VERSION "10.8"

NS_ :

BS_:

BU_: SCC ESR
VAL_TABLE_ Value_Table_Track_Status 7 "New Coasting Target" 6 "Invalid Coasting Target" 5 "Merged Target" 4 "Coasting Target" 3 "Updated Target" 2 "New Updated Target" 1 "New Target" 0 "No Target" ;

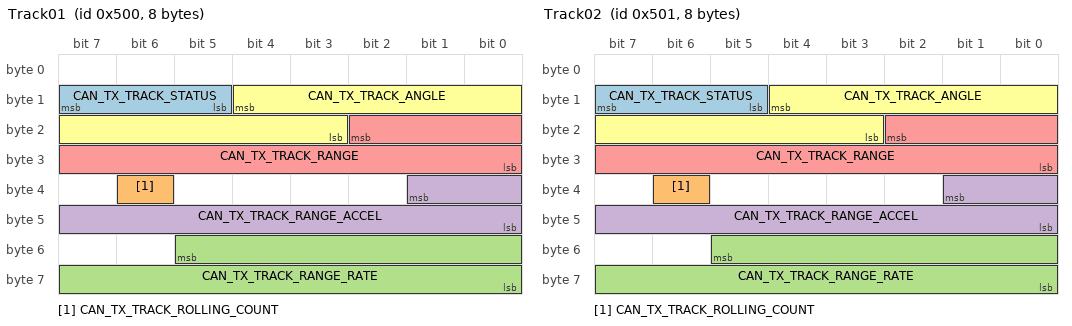
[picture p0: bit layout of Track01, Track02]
BO_ 1280 Track01: 8 ESR
 SG_ CAN_TX_TRACK_STATUS : 15|3@0+ (1,0) [0|7] "" Vector__XXX
 SG_ CAN_TX_TRACK_ROLLING_COUNT : 38|1@0+ (1,0) [0|1] "" Vector__XXX
 SG_ CAN_TX_TRACK_RANGE_RATE : 53|14@0- (0.01,0) [-81.92|81.91] "m/s" Vector__XXX
 SG_ CAN_TX_TRACK_RANGE_ACCEL : 33|10@0- (0.05,0) [-25.6|25.55] "m/s/s" Vector__XXX
 SG_ CAN_TX_TRACK_RANGE : 18|11@0+ (0.1,0) [0|204.7] "m" Vector__XXX
 SG_ CAN_TX_TRACK_ANGLE : 12|10@0- (0.1,0) [-51.2|51.1] "deg" Vector__XXX

BO_ 1281 Track02: 8 ESR
 SG_ CAN_TX_TRACK_STATUS : 15|3@0+ (1,0) [0|7] "" Vector__XXX
 SG_ CAN_TX_TRACK_ROLLING_COUNT : 38|1@0+ (1,0) [0|1] "" Vector__XXX
 SG_ CAN_TX_TRACK_RANGE_RATE : 53|14@0- (0.01,0) [-81.92|81.91] "m/s" Vector__XXX
 SG_ CAN_TX_TRACK_RANGE_ACCEL : 33|10@0- (0.05,0) [-25.6|25.55] "m/s/s" Vector__XXX
 SG_ CAN_TX_TRACK_RANGE : 18|11@0+ (0.1,0) [0|204.7] "m" Vector__XXX
 SG_ CAN_TX_TRACK_ANGLE : 12|10@0- (0.1,0) [-51.2|51.1] "deg" Vector__XXX

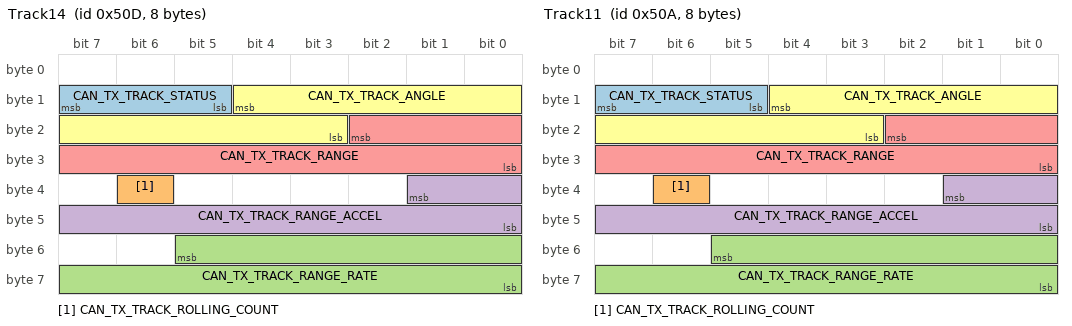
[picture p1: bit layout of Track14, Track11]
BO_ 1293 Track14: 8 ESR
 SG_ CAN_TX_TRACK_STATUS : 15|3@0+ (1,0) [0|7] "" Vector__XXX
 SG_ CAN_TX_TRACK_ROLLING_COUNT : 38|1@0+ (1,0) [0|1] "" Vector__XXX
 SG_ CAN_TX_TRACK_RANGE_RATE : 53|14@0- (0.01,0) [-81.92|81.91] "m/s" Vector__XXX
 SG_ CAN_TX_TRACK_RANGE_ACCEL : 33|10@0- (0.05,0) [-25.6|25.55] "m/s/s" Vector__XXX
 SG_ CAN_TX_TRACK_RANGE : 18|11@0+ (0.1,0) [0|204.7] "m" Vector__XXX
 SG_ CAN_TX_TRACK_ANGLE : 12|10@0- (0.1,0) [-51.2|51.1] "deg" Vector__XXX

BO_ 1290 Track11: 8 ESR
 SG_ CAN_TX_TRACK_STATUS : 15|3@0+ (1,0) [0|7] "" Vector__XXX
 SG_ CAN_TX_TRACK_ROLLING_COUNT : 38|1@0+ (1,0) [0|1] "" Vector__XXX
 SG_ CAN_TX_TRACK_RANGE_RATE : 53|14@0- (0.01,0) [-81.92|81.91] "m/s" Vector__XXX
 SG_ CAN_TX_TRACK_RANGE_ACCEL : 33|10@0- (0.05,0) [-25.6|25.55] "m/s/s" Vector__XXX
 SG_ CAN_TX_TRACK_RANGE : 18|11@0+ (0.1,0) [0|204.7] "m" Vector__XXX
 SG_ CAN_TX_TRACK_ANGLE : 12|10@0- (0.1,0) [-51.2|51.1] "deg" Vector__XXX

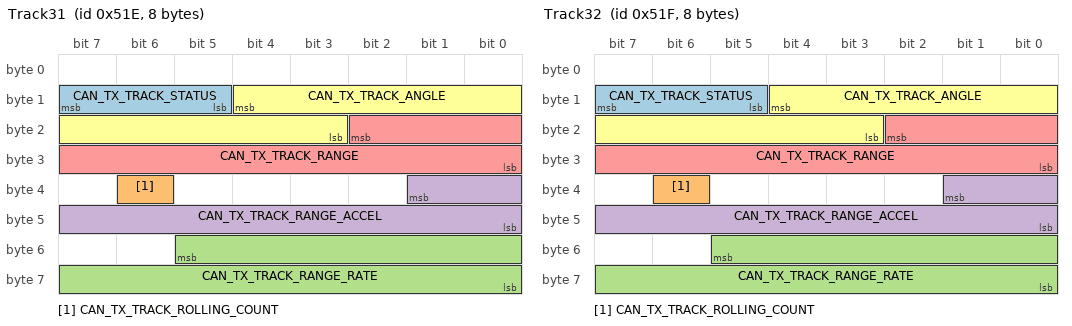
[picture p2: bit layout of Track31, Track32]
BO_ 1310 Track31: 8 ESR
 SG_ CAN_TX_TRACK_STATUS : 15|3@0+ (1,0) [0|7] "" Vector__XXX
 SG_ CAN_TX_TRACK_ROLLING_COUNT : 38|1@0+ (1,0) [0|1] "" Vector__XXX
 SG_ CAN_TX_TRACK_RANGE_RATE : 53|14@0- (0.01,0) [-81.92|81.91] "m/s" Vector__XXX
 SG_ CAN_TX_TRACK_RANGE_ACCEL : 33|10@0- (0.05,0) [-25.6|25.55] "m/s/s" Vector__XXX
 SG_ CAN_TX_TRACK_RANGE : 18|11@0+ (0.1,0) [0|204.7] "m" Vector__XXX
 SG_ CAN_TX_TRACK_ANGLE : 12|10@0- (0.1,0) [-51.2|51.1] "deg" Vector__XXX

BO_ 1311 Track32: 8 ESR
 SG_ CAN_TX_TRACK_STATUS : 15|3@0+ (1,0) [0|7] "" Vector__XXX
 SG_ CAN_TX_TRACK_ROLLING_COUNT : 38|1@0+ (1,0) [0|1] "" Vector__XXX
 SG_ CAN_TX_TRACK_RANGE_RATE : 53|14@0- (0.01,0) [-81.92|81.91] "m/s" Vector__XXX
 SG_ CAN_TX_TRACK_RANGE_ACCEL : 33|10@0- (0.05,0) [-25.6|25.55] "m/s/s" Vector__XXX
 SG_ CAN_TX_TRACK_RANGE : 18|11@0+ (0.1,0) [0|204.7] "m" Vector__XXX
 SG_ CAN_TX_TRACK_ANGLE : 12|10@0- (0.1,0) [-51.2|51.1] "deg" Vector__XXX

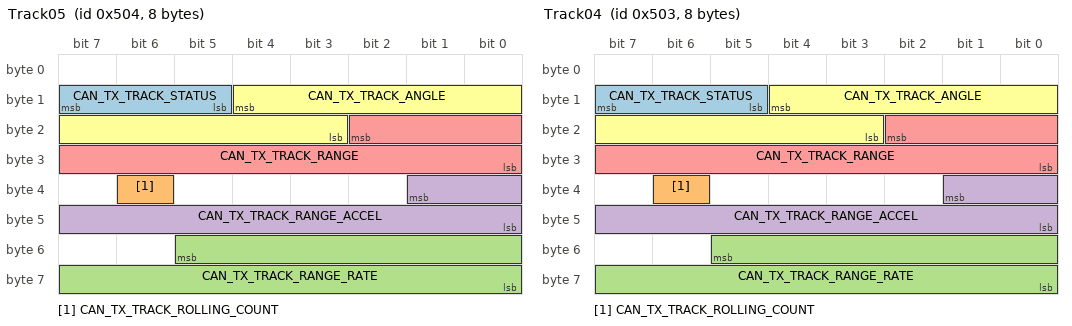
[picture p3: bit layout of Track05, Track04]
BO_ 1284 Track05: 8 ESR
 SG_ CAN_TX_TRACK_STATUS : 15|3@0+ (1,0) [0|7] "" Vector__XXX
 SG_ CAN_TX_TRACK_ROLLING_COUNT : 38|1@0+ (1,0) [0|1] "" Vector__XXX
 SG_ CAN_TX_TRACK_RANGE_RATE : 53|14@0- (0.01,0) [-81.92|81.91] "m/s" Vector__XXX
 SG_ CAN_TX_TRACK_RANGE_ACCEL : 33|10@0- (0.05,0) [-25.6|25.55] "m/s/s" Vector__XXX
 SG_ CAN_TX_TRACK_RANGE : 18|11@0+ (0.1,0) [0|204.7] "m" Vector__XXX
 SG_ CAN_TX_TRACK_ANGLE : 12|10@0- (0.1,0) [-51.2|51.1] "deg" Vector__XXX

BO_ 1283 Track04: 8 ESR
 SG_ CAN_TX_TRACK_STATUS : 15|3@0+ (1,0) [0|7] "" Vector__XXX
 SG_ CAN_TX_TRACK_ROLLING_COUNT : 38|1@0+ (1,0) [0|1] "" Vector__XXX
 SG_ CAN_TX_TRACK_RANGE_RATE : 53|14@0- (0.01,0) [-81.92|81.91] "m/s" Vector__XXX
 SG_ CAN_TX_TRACK_RANGE_ACCEL : 33|10@0- (0.05,0) [-25.6|25.55] "m/s/s" Vector__XXX
 SG_ CAN_TX_TRACK_RANGE : 18|11@0+ (0.1,0) [0|204.7] "m" Vector__XXX
 SG_ CAN_TX_TRACK_ANGLE : 12|10@0- (0.1,0) [-51.2|51.1] "deg" Vector__XXX

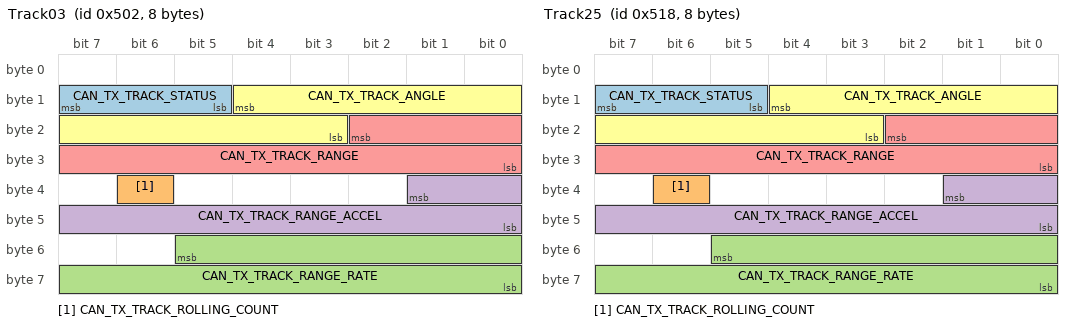
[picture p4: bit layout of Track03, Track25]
BO_ 1282 Track03: 8 ESR
 SG_ CAN_TX_TRACK_STATUS : 15|3@0+ (1,0) [0|7] "" Vector__XXX
 SG_ CAN_TX_TRACK_ROLLING_COUNT : 38|1@0+ (1,0) [0|1] "" Vector__XXX
 SG_ CAN_TX_TRACK_RANGE_RATE : 53|14@0- (0.01,0) [-81.92|81.91] "m/s" Vector__XXX
 SG_ CAN_TX_TRACK_RANGE_ACCEL : 33|10@0- (0.05,0) [-25.6|25.55] "m/s/s" Vector__XXX
 SG_ CAN_TX_TRACK_RANGE : 18|11@0+ (0.1,0) [0|204.7] "m" Vector__XXX
 SG_ CAN_TX_TRACK_ANGLE : 12|10@0- (0.1,0) [-51.2|51.1] "deg" Vector__XXX

BO_ 1304 Track25: 8 ESR
 SG_ CAN_TX_TRACK_STATUS : 15|3@0+ (1,0) [0|7] "" Vector__XXX
 SG_ CAN_TX_TRACK_ROLLING_COUNT : 38|1@0+ (1,0) [0|1] "" Vector__XXX
 SG_ CAN_TX_TRACK_RANGE_RATE : 53|14@0- (0.01,0) [-81.92|81.91] "m/s" Vector__XXX
 SG_ CAN_TX_TRACK_RANGE_ACCEL : 33|10@0- (0.05,0) [-25.6|25.55] "m/s/s" Vector__XXX
 SG_ CAN_TX_TRACK_RANGE : 18|11@0+ (0.1,0) [0|204.7] "m" Vector__XXX
 SG_ CAN_TX_TRACK_ANGLE : 12|10@0- (0.1,0) [-51.2|51.1] "deg" Vector__XXX

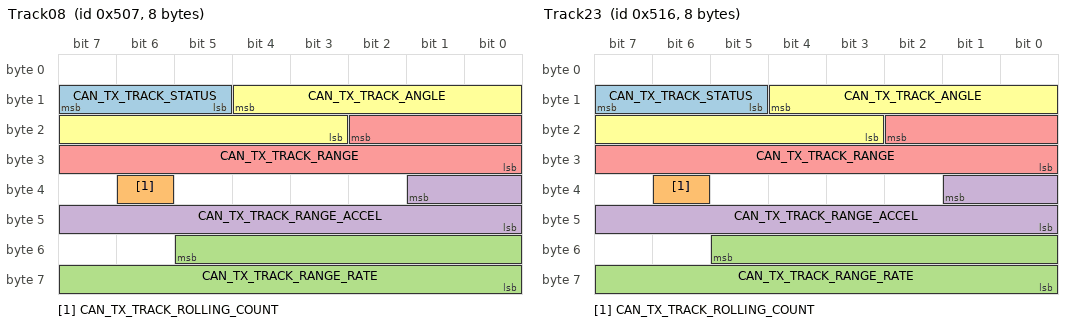
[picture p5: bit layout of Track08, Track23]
BO_ 1287 Track08: 8 ESR
 SG_ CAN_TX_TRACK_STATUS : 15|3@0+ (1,0) [0|7] "" Vector__XXX
 SG_ CAN_TX_TRACK_ROLLING_COUNT : 38|1@0+ (1,0) [0|1] "" Vector__XXX
 SG_ CAN_TX_TRACK_RANGE_RATE : 53|14@0- (0.01,0) [-81.92|81.91] "m/s" Vector__XXX
 SG_ CAN_TX_TRACK_RANGE_ACCEL : 33|10@0- (0.05,0) [-25.6|25.55] "m/s/s" Vector__XXX
 SG_ CAN_TX_TRACK_RANGE : 18|11@0+ (0.1,0) [0|204.7] "m" Vector__XXX
 SG_ CAN_TX_TRACK_ANGLE : 12|10@0- (0.1,0) [-51.2|51.1] "deg" Vector__XXX

BO_ 1302 Track23: 8 ESR
 SG_ CAN_TX_TRACK_STATUS : 15|3@0+ (1,0) [0|7] "" Vector__XXX
 SG_ CAN_TX_TRACK_ROLLING_COUNT : 38|1@0+ (1,0) [0|1] "" Vector__XXX
 SG_ CAN_TX_TRACK_RANGE_RATE : 53|14@0- (0.01,0) [-81.92|81.91] "m/s" Vector__XXX
 SG_ CAN_TX_TRACK_RANGE_ACCEL : 33|10@0- (0.05,0) [-25.6|25.55] "m/s/s" Vector__XXX
 SG_ CAN_TX_TRACK_RANGE : 18|11@0+ (0.1,0) [0|204.7] "m" Vector__XXX
 SG_ CAN_TX_TRACK_ANGLE : 12|10@0- (0.1,0) [-51.2|51.1] "deg" Vector__XXX

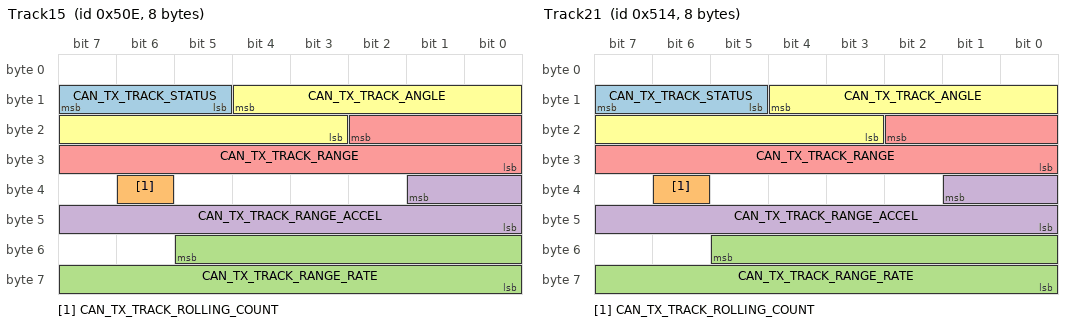
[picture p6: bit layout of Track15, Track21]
BO_ 1294 Track15: 8 ESR
 SG_ CAN_TX_TRACK_STATUS : 15|3@0+ (1,0) [0|7] "" Vector__XXX
 SG_ CAN_TX_TRACK_ROLLING_COUNT : 38|1@0+ (1,0) [0|1] "" Vector__XXX
 SG_ CAN_TX_TRACK_RANGE_RATE : 53|14@0- (0.01,0) [-81.92|81.91] "m/s" Vector__XXX
 SG_ CAN_TX_TRACK_RANGE_ACCEL : 33|10@0- (0.05,0) [-25.6|25.55] "m/s/s" Vector__XXX
 SG_ CAN_TX_TRACK_RANGE : 18|11@0+ (0.1,0) [0|204.7] "m" Vector__XXX
 SG_ CAN_TX_TRACK_ANGLE : 12|10@0- (0.1,0) [-51.2|51.1] "deg" Vector__XXX

BO_ 1300 Track21: 8 ESR
 SG_ CAN_TX_TRACK_STATUS : 15|3@0+ (1,0) [0|7] "" Vector__XXX
 SG_ CAN_TX_TRACK_ROLLING_COUNT : 38|1@0+ (1,0) [0|1] "" Vector__XXX
 SG_ CAN_TX_TRACK_RANGE_RATE : 53|14@0- (0.01,0) [-81.92|81.91] "m/s" Vector__XXX
 SG_ CAN_TX_TRACK_RANGE_ACCEL : 33|10@0- (0.05,0) [-25.6|25.55] "m/s/s" Vector__XXX
 SG_ CAN_TX_TRACK_RANGE : 18|11@0+ (0.1,0) [0|204.7] "m" Vector__XXX
 SG_ CAN_TX_TRACK_ANGLE : 12|10@0- (0.1,0) [-51.2|51.1] "deg" Vector__XXX

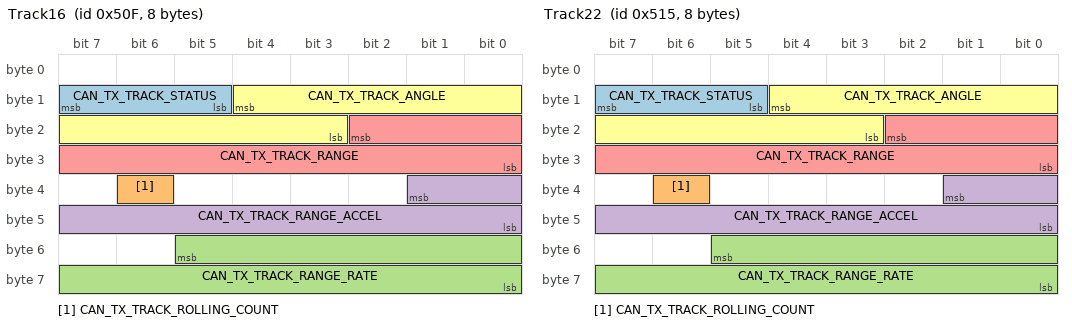
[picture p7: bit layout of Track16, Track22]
BO_ 1295 Track16: 8 ESR
 SG_ CAN_TX_TRACK_STATUS : 15|3@0+ (1,0) [0|7] "" Vector__XXX
 SG_ CAN_TX_TRACK_ROLLING_COUNT : 38|1@0+ (1,0) [0|1] "" Vector__XXX
 SG_ CAN_TX_TRACK_RANGE_RATE : 53|14@0- (0.01,0) [-81.92|81.91] "m/s" Vector__XXX
 SG_ CAN_TX_TRACK_RANGE_ACCEL : 33|10@0- (0.05,0) [-25.6|25.55] "m/s/s" Vector__XXX
 SG_ CAN_TX_TRACK_RANGE : 18|11@0+ (0.1,0) [0|204.7] "m" Vector__XXX
 SG_ CAN_TX_TRACK_ANGLE : 12|10@0- (0.1,0) [-51.2|51.1] "deg" Vector__XXX

BO_ 1301 Track22: 8 ESR
 SG_ CAN_TX_TRACK_STATUS : 15|3@0+ (1,0) [0|7] "" Vector__XXX
 SG_ CAN_TX_TRACK_ROLLING_COUNT : 38|1@0+ (1,0) [0|1] "" Vector__XXX
 SG_ CAN_TX_TRACK_RANGE_RATE : 53|14@0- (0.01,0) [-81.92|81.91] "m/s" Vector__XXX
 SG_ CAN_TX_TRACK_RANGE_ACCEL : 33|10@0- (0.05,0) [-25.6|25.55] "m/s/s" Vector__XXX
 SG_ CAN_TX_TRACK_RANGE : 18|11@0+ (0.1,0) [0|204.7] "m" Vector__XXX
 SG_ CAN_TX_TRACK_ANGLE : 12|10@0- (0.1,0) [-51.2|51.1] "deg" Vector__XXX

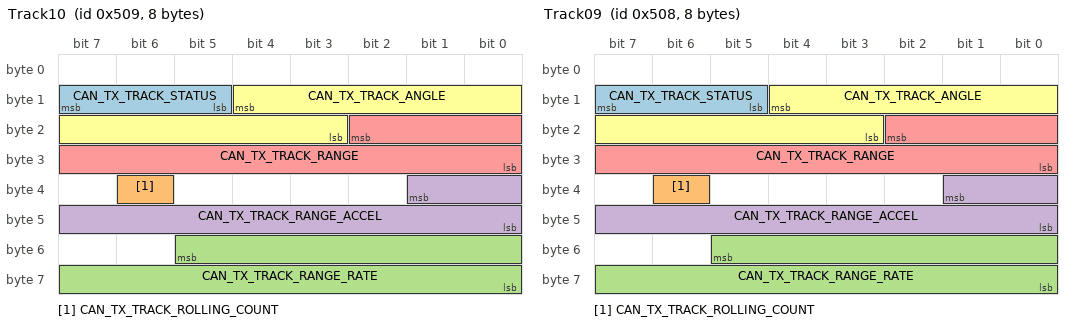
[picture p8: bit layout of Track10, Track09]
BO_ 1289 Track10: 8 ESR
 SG_ CAN_TX_TRACK_STATUS : 15|3@0+ (1,0) [0|7] "" Vector__XXX
 SG_ CAN_TX_TRACK_ROLLING_COUNT : 38|1@0+ (1,0) [0|1] "" Vector__XXX
 SG_ CAN_TX_TRACK_RANGE_RATE : 53|14@0- (0.01,0) [-81.92|81.91] "m/s" Vector__XXX
 SG_ CAN_TX_TRACK_RANGE_ACCEL : 33|10@0- (0.05,0) [-25.6|25.55] "m/s/s" Vector__XXX
 SG_ CAN_TX_TRACK_RANGE : 18|11@0+ (0.1,0) [0|204.7] "m" Vector__XXX
 SG_ CAN_TX_TRACK_ANGLE : 12|10@0- (0.1,0) [-51.2|51.1] "deg" Vector__XXX

BO_ 1288 Track09: 8 ESR
 SG_ CAN_TX_TRACK_STATUS : 15|3@0+ (1,0) [0|7] "" Vector__XXX
 SG_ CAN_TX_TRACK_ROLLING_COUNT : 38|1@0+ (1,0) [0|1] "" Vector__XXX
 SG_ CAN_TX_TRACK_RANGE_RATE : 53|14@0- (0.01,0) [-81.92|81.91] "m/s" Vector__XXX
 SG_ CAN_TX_TRACK_RANGE_ACCEL : 33|10@0- (0.05,0) [-25.6|25.55] "m/s/s" Vector__XXX
 SG_ CAN_TX_TRACK_RANGE : 18|11@0+ (0.1,0) [0|204.7] "m" Vector__XXX
 SG_ CAN_TX_TRACK_ANGLE : 12|10@0- (0.1,0) [-51.2|51.1] "deg" Vector__XXX

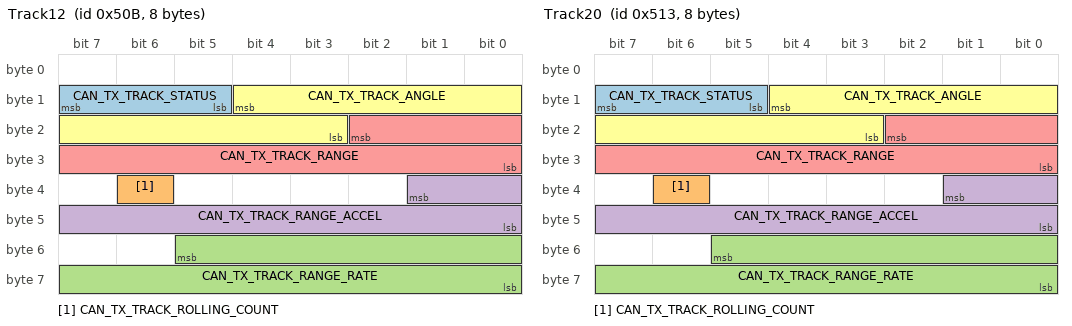
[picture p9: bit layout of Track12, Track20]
BO_ 1291 Track12: 8 ESR
 SG_ CAN_TX_TRACK_STATUS : 15|3@0+ (1,0) [0|7] "" Vector__XXX
 SG_ CAN_TX_TRACK_ROLLING_COUNT : 38|1@0+ (1,0) [0|1] "" Vector__XXX
 SG_ CAN_TX_TRACK_RANGE_RATE : 53|14@0- (0.01,0) [-81.92|81.91] "m/s" Vector__XXX
 SG_ CAN_TX_TRACK_RANGE_ACCEL : 33|10@0- (0.05,0) [-25.6|25.55] "m/s/s" Vector__XXX
 SG_ CAN_TX_TRACK_RANGE : 18|11@0+ (0.1,0) [0|204.7] "m" Vector__XXX
 SG_ CAN_TX_TRACK_ANGLE : 12|10@0- (0.1,0) [-51.2|51.1] "deg" Vector__XXX

BO_ 1299 Track20: 8 ESR
 SG_ CAN_TX_TRACK_STATUS : 15|3@0+ (1,0) [0|7] "" Vector__XXX
 SG_ CAN_TX_TRACK_ROLLING_COUNT : 38|1@0+ (1,0) [0|1] "" Vector__XXX
 SG_ CAN_TX_TRACK_RANGE_RATE : 53|14@0- (0.01,0) [-81.92|81.91] "m/s" Vector__XXX
 SG_ CAN_TX_TRACK_RANGE_ACCEL : 33|10@0- (0.05,0) [-25.6|25.55] "m/s/s" Vector__XXX
 SG_ CAN_TX_TRACK_RANGE : 18|11@0+ (0.1,0) [0|204.7] "m" Vector__XXX
 SG_ CAN_TX_TRACK_ANGLE : 12|10@0- (0.1,0) [-51.2|51.1] "deg" Vector__XXX

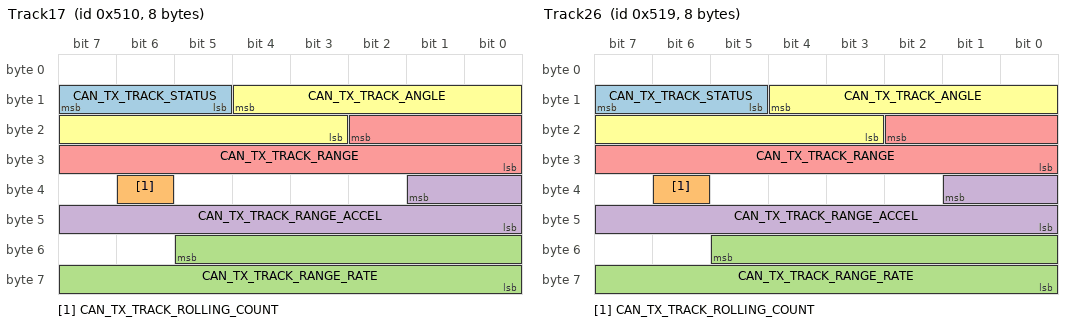
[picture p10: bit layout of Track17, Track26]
BO_ 1296 Track17: 8 ESR
 SG_ CAN_TX_TRACK_STATUS : 15|3@0+ (1,0) [0|7] "" Vector__XXX
 SG_ CAN_TX_TRACK_ROLLING_COUNT : 38|1@0+ (1,0) [0|1] "" Vector__XXX
 SG_ CAN_TX_TRACK_RANGE_RATE : 53|14@0- (0.01,0) [-81.92|81.91] "m/s" Vector__XXX
 SG_ CAN_TX_TRACK_RANGE_ACCEL : 33|10@0- (0.05,0) [-25.6|25.55] "m/s/s" Vector__XXX
 SG_ CAN_TX_TRACK_RANGE : 18|11@0+ (0.1,0) [0|204.7] "m" Vector__XXX
 SG_ CAN_TX_TRACK_ANGLE : 12|10@0- (0.1,0) [-51.2|51.1] "deg" Vector__XXX

BO_ 1305 Track26: 8 ESR
 SG_ CAN_TX_TRACK_STATUS : 15|3@0+ (1,0) [0|7] "" Vector__XXX
 SG_ CAN_TX_TRACK_ROLLING_COUNT : 38|1@0+ (1,0) [0|1] "" Vector__XXX
 SG_ CAN_TX_TRACK_RANGE_RATE : 53|14@0- (0.01,0) [-81.92|81.91] "m/s" Vector__XXX
 SG_ CAN_TX_TRACK_RANGE_ACCEL : 33|10@0- (0.05,0) [-25.6|25.55] "m/s/s" Vector__XXX
 SG_ CAN_TX_TRACK_RANGE : 18|11@0+ (0.1,0) [0|204.7] "m" Vector__XXX
 SG_ CAN_TX_TRACK_ANGLE : 12|10@0- (0.1,0) [-51.2|51.1] "deg" Vector__XXX

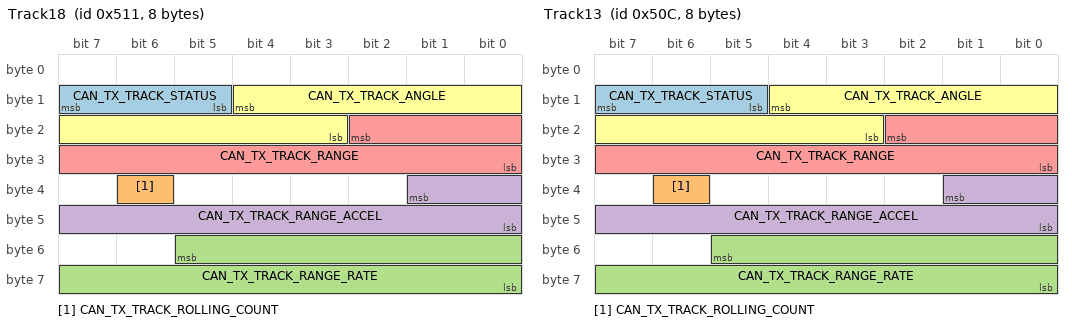
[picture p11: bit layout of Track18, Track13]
BO_ 1297 Track18: 8 ESR
 SG_ CAN_TX_TRACK_STATUS : 15|3@0+ (1,0) [0|7] "" Vector__XXX
 SG_ CAN_TX_TRACK_ROLLING_COUNT : 38|1@0+ (1,0) [0|1] "" Vector__XXX
 SG_ CAN_TX_TRACK_RANGE_RATE : 53|14@0- (0.01,0) [-81.92|81.91] "m/s" Vector__XXX
 SG_ CAN_TX_TRACK_RANGE_ACCEL : 33|10@0- (0.05,0) [-25.6|25.55] "m/s/s" Vector__XXX
 SG_ CAN_TX_TRACK_RANGE : 18|11@0+ (0.1,0) [0|204.7] "m" Vector__XXX
 SG_ CAN_TX_TRACK_ANGLE : 12|10@0- (0.1,0) [-51.2|51.1] "deg" Vector__XXX

BO_ 1292 Track13: 8 ESR
 SG_ CAN_TX_TRACK_STATUS : 15|3@0+ (1,0) [0|7] "" Vector__XXX
 SG_ CAN_TX_TRACK_ROLLING_COUNT : 38|1@0+ (1,0) [0|1] "" Vector__XXX
 SG_ CAN_TX_TRACK_RANGE_RATE : 53|14@0- (0.01,0) [-81.92|81.91] "m/s" Vector__XXX
 SG_ CAN_TX_TRACK_RANGE_ACCEL : 33|10@0- (0.05,0) [-25.6|25.55] "m/s/s" Vector__XXX
 SG_ CAN_TX_TRACK_RANGE : 18|11@0+ (0.1,0) [0|204.7] "m" Vector__XXX
 SG_ CAN_TX_TRACK_ANGLE : 12|10@0- (0.1,0) [-51.2|51.1] "deg" Vector__XXX

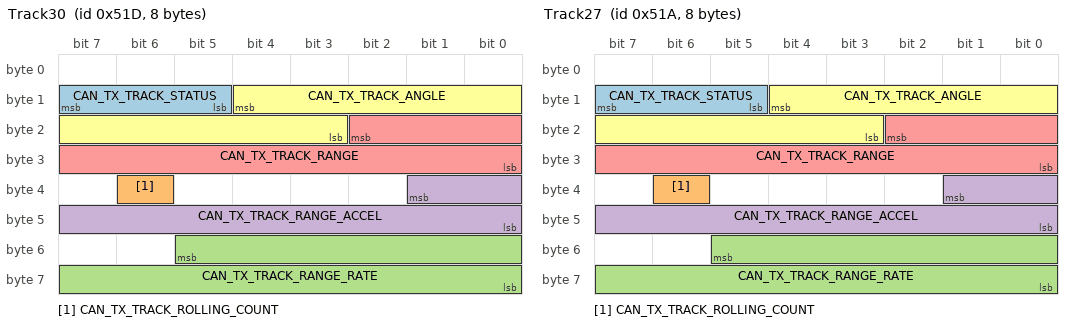
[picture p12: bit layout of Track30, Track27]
BO_ 1309 Track30: 8 ESR
 SG_ CAN_TX_TRACK_STATUS : 15|3@0+ (1,0) [0|7] "" Vector__XXX
 SG_ CAN_TX_TRACK_ROLLING_COUNT : 38|1@0+ (1,0) [0|1] "" Vector__XXX
 SG_ CAN_TX_TRACK_RANGE_RATE : 53|14@0- (0.01,0) [-81.92|81.91] "m/s" Vector__XXX
 SG_ CAN_TX_TRACK_RANGE_ACCEL : 33|10@0- (0.05,0) [-25.6|25.55] "m/s/s" Vector__XXX
 SG_ CAN_TX_TRACK_RANGE : 18|11@0+ (0.1,0) [0|204.7] "m" Vector__XXX
 SG_ CAN_TX_TRACK_ANGLE : 12|10@0- (0.1,0) [-51.2|51.1] "deg" Vector__XXX

BO_ 1306 Track27: 8 ESR
 SG_ CAN_TX_TRACK_STATUS : 15|3@0+ (1,0) [0|7] "" Vector__XXX
 SG_ CAN_TX_TRACK_ROLLING_COUNT : 38|1@0+ (1,0) [0|1] "" Vector__XXX
 SG_ CAN_TX_TRACK_RANGE_RATE : 53|14@0- (0.01,0) [-81.92|81.91] "m/s" Vector__XXX
 SG_ CAN_TX_TRACK_RANGE_ACCEL : 33|10@0- (0.05,0) [-25.6|25.55] "m/s/s" Vector__XXX
 SG_ CAN_TX_TRACK_RANGE : 18|11@0+ (0.1,0) [0|204.7] "m" Vector__XXX
 SG_ CAN_TX_TRACK_ANGLE : 12|10@0- (0.1,0) [-51.2|51.1] "deg" Vector__XXX

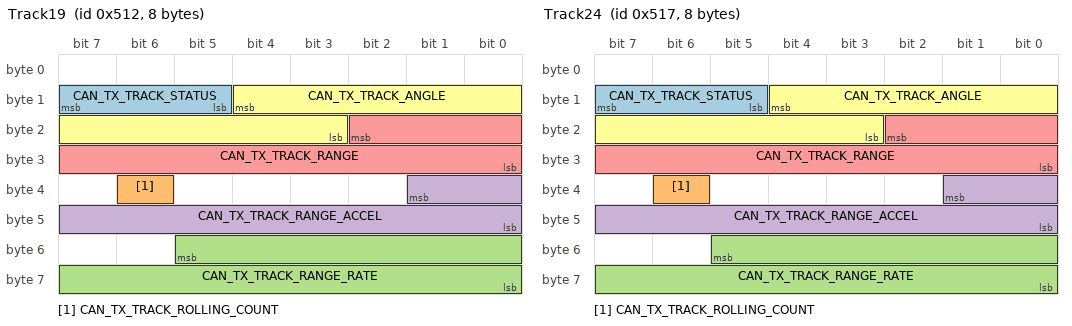
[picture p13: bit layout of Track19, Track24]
BO_ 1298 Track19: 8 ESR
 SG_ CAN_TX_TRACK_STATUS : 15|3@0+ (1,0) [0|7] "" Vector__XXX
 SG_ CAN_TX_TRACK_ROLLING_COUNT : 38|1@0+ (1,0) [0|1] "" Vector__XXX
 SG_ CAN_TX_TRACK_RANGE_RATE : 53|14@0- (0.01,0) [-81.92|81.91] "m/s" Vector__XXX
 SG_ CAN_TX_TRACK_RANGE_ACCEL : 33|10@0- (0.05,0) [-25.6|25.55] "m/s/s" Vector__XXX
 SG_ CAN_TX_TRACK_RANGE : 18|11@0+ (0.1,0) [0|204.7] "m" Vector__XXX
 SG_ CAN_TX_TRACK_ANGLE : 12|10@0- (0.1,0) [-51.2|51.1] "deg" Vector__XXX

BO_ 1303 Track24: 8 ESR
 SG_ CAN_TX_TRACK_STATUS : 15|3@0+ (1,0) [0|7] "" Vector__XXX
 SG_ CAN_TX_TRACK_ROLLING_COUNT : 38|1@0+ (1,0) [0|1] "" Vector__XXX
 SG_ CAN_TX_TRACK_RANGE_RATE : 53|14@0- (0.01,0) [-81.92|81.91] "m/s" Vector__XXX
 SG_ CAN_TX_TRACK_RANGE_ACCEL : 33|10@0- (0.05,0) [-25.6|25.55] "m/s/s" Vector__XXX
 SG_ CAN_TX_TRACK_RANGE : 18|11@0+ (0.1,0) [0|204.7] "m" Vector__XXX
 SG_ CAN_TX_TRACK_ANGLE : 12|10@0- (0.1,0) [-51.2|51.1] "deg" Vector__XXX

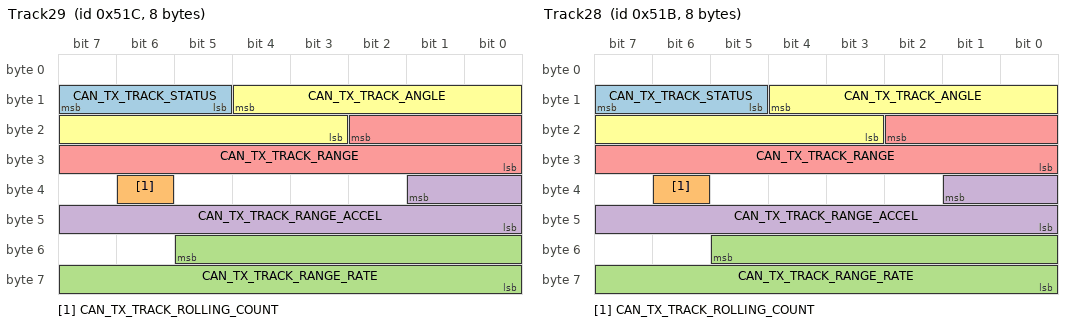
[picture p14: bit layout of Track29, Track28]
BO_ 1308 Track29: 8 ESR
 SG_ CAN_TX_TRACK_STATUS : 15|3@0+ (1,0) [0|7] "" Vector__XXX
 SG_ CAN_TX_TRACK_ROLLING_COUNT : 38|1@0+ (1,0) [0|1] "" Vector__XXX
 SG_ CAN_TX_TRACK_RANGE_RATE : 53|14@0- (0.01,0) [-81.92|81.91] "m/s" Vector__XXX
 SG_ CAN_TX_TRACK_RANGE_ACCEL : 33|10@0- (0.05,0) [-25.6|25.55] "m/s/s" Vector__XXX
 SG_ CAN_TX_TRACK_RANGE : 18|11@0+ (0.1,0) [0|204.7] "m" Vector__XXX
 SG_ CAN_TX_TRACK_ANGLE : 12|10@0- (0.1,0) [-51.2|51.1] "deg" Vector__XXX

BO_ 1307 Track28: 8 ESR
 SG_ CAN_TX_TRACK_STATUS : 15|3@0+ (1,0) [0|7] "" Vector__XXX
 SG_ CAN_TX_TRACK_ROLLING_COUNT : 38|1@0+ (1,0) [0|1] "" Vector__XXX
 SG_ CAN_TX_TRACK_RANGE_RATE : 53|14@0- (0.01,0) [-81.92|81.91] "m/s" Vector__XXX
 SG_ CAN_TX_TRACK_RANGE_ACCEL : 33|10@0- (0.05,0) [-25.6|25.55] "m/s/s" Vector__XXX
 SG_ CAN_TX_TRACK_RANGE : 18|11@0+ (0.1,0) [0|204.7] "m" Vector__XXX
 SG_ CAN_TX_TRACK_ANGLE : 12|10@0- (0.1,0) [-51.2|51.1] "deg" Vector__XXX

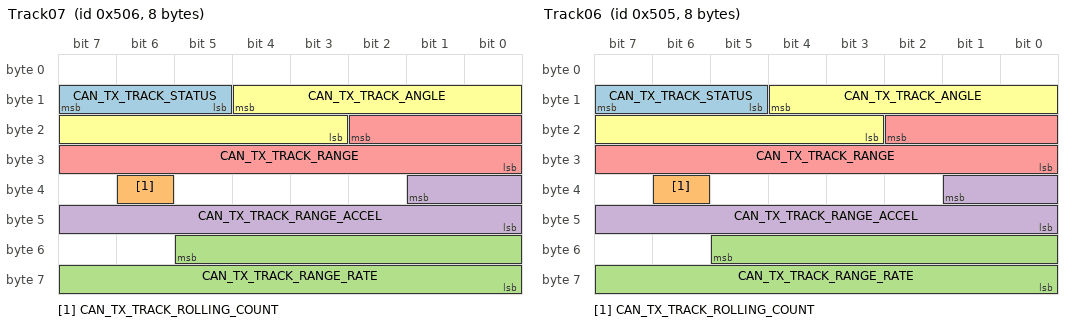
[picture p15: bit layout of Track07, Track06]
BO_ 1286 Track07: 8 ESR
 SG_ CAN_TX_TRACK_STATUS : 15|3@0+ (1,0) [0|7] "" Vector__XXX
 SG_ CAN_TX_TRACK_ROLLING_COUNT : 38|1@0+ (1,0) [0|1] "" Vector__XXX
 SG_ CAN_TX_TRACK_RANGE_RATE : 53|14@0- (0.01,0) [-81.92|81.91] "m/s" Vector__XXX
 SG_ CAN_TX_TRACK_RANGE_ACCEL : 33|10@0- (0.05,0) [-25.6|25.55] "m/s/s" Vector__XXX
 SG_ CAN_TX_TRACK_RANGE : 18|11@0+ (0.1,0) [0|204.7] "m" Vector__XXX
 SG_ CAN_TX_TRACK_ANGLE : 12|10@0- (0.1,0) [-51.2|51.1] "deg" Vector__XXX

BO_ 1285 Track06: 8 ESR
 SG_ CAN_TX_TRACK_STATUS : 15|3@0+ (1,0) [0|7] "" Vector__XXX
 SG_ CAN_TX_TRACK_ROLLING_COUNT : 38|1@0+ (1,0) [0|1] "" Vector__XXX
 SG_ CAN_TX_TRACK_RANGE_RATE : 53|14@0- (0.01,0) [-81.92|81.91] "m/s" Vector__XXX
 SG_ CAN_TX_TRACK_RANGE_ACCEL : 33|10@0- (0.05,0) [-25.6|25.55] "m/s/s" Vector__XXX
 SG_ CAN_TX_TRACK_RANGE : 18|11@0+ (0.1,0) [0|204.7] "m" Vector__XXX
 SG_ CAN_TX_TRACK_ANGLE : 12|10@0- (0.1,0) [-51.2|51.1] "deg" Vector__XXX

BA_DEF_ SG_  "GenSigSendType" ENUM  "Cyclic","OnWrite","OnWriteWithRepetition","OnChange","OnChangeWithRepetition","IfActive","IfActiveWithRepetition","NoSigSendType";
BA_DEF_ BO_  "GenMsgILSupport" ENUM  "No","Yes";
BA_DEF_ BO_  "GenMsgCycleTime" INT 2 50000;
BA_DEF_ BO_  "GenMsgDelayTime" INT 1 1000;
BA_DEF_ BO_  "GenMsgNrOfRepetitions" INT 1 999999;
BA_DEF_ BO_  "GenMsgSendType" ENUM  "Cyclic","not_used","not_used","not_used","not_used","not_used","not_used","IfActive","NoMsgSendType";
BA_DEF_ BU_  "ILUsed" ENUM  "No","Yes";
BA_DEF_  "DBName" STRING ;
BA_DEF_  "Baudrate" INT 50000 1000000;
BA_DEF_  "BusType" STRING ;
BA_DEF_  "Manufacturer" STRING ;
BA_DEF_REL_ BU_SG_REL_  "GenSigTimeoutTime" INT 0 5000;
BA_DEF_DEF_  "GenSigSendType" "Cyclic";
BA_DEF_DEF_  "GenMsgILSupport" "Yes";
BA_DEF_DEF_  "GenMsgCycleTime" 50;
BA_DEF_DEF_  "GenMsgDelayTime" 10;
BA_DEF_DEF_  "GenMsgNrOfRepetitions" 3;
BA_DEF_DEF_  "GenMsgSendType" "Cyclic";
BA_DEF_DEF_  "ILUsed" "Yes";
BA_DEF_DEF_  "DBName" "";
BA_DEF_DEF_  "Baudrate" 500000;
BA_DEF_DEF_  "BusType" "CAN";
BA_DEF_DEF_  "Manufacturer" "Geely";
BA_DEF_DEF_REL_ "GenSigTimeoutTime" 500;
BA_ "DBName" "LRR20_F_CAN";
VAL_ 1280 CAN_TX_TRACK_STATUS 7 "New Coasting Target" 6 "Invalid Coasting Target" 5 "Merged Target" 4 "Coasting Target" 3 "Updated Target" 2 "New Updated Target" 1 "New Target" 0 "No Target" ;
VAL_ 1281 CAN_TX_TRACK_STATUS 7 "New Coasting Target" 6 "Invalid Coasting Target" 5 "Merged Target" 4 "Coasting Target" 3 "Updated Target" 2 "New Updated Target" 1 "New Target" 0 "No Target" ;
VAL_ 1293 CAN_TX_TRACK_STATUS 7 "New Coasting Target" 6 "Invalid Coasting Target" 5 "Merged Target" 4 "Coasting Target" 3 "Updated Target" 2 "New Updated Target" 1 "New Target" 0 "No Target" ;
VAL_ 1290 CAN_TX_TRACK_STATUS 7 "New Coasting Target" 6 "Invalid Coasting Target" 5 "Merged Target" 4 "Coasting Target" 3 "Updated Target" 2 "New Updated Target" 1 "New Target" 0 "No Target" ;
VAL_ 1310 CAN_TX_TRACK_STATUS 7 "New Coasting Target" 6 "Invalid Coasting Target" 5 "Merged Target" 4 "Coasting Target" 3 "Updated Target" 2 "New Updated Target" 1 "New Target" 0 "No Target" ;
VAL_ 1311 CAN_TX_TRACK_STATUS 7 "New Coasting Target" 6 "Invalid Coasting Target" 5 "Merged Target" 4 "Coasting Target" 3 "Updated Target" 2 "New Updated Target" 1 "New Target" 0 "No Target" ;
VAL_ 1284 CAN_TX_TRACK_STATUS 7 "New Coasting Target" 6 "Invalid Coasting Target" 5 "Merged Target" 4 "Coasting Target" 3 "Updated Target" 2 "New Updated Target" 1 "New Target" 0 "No Target" ;
VAL_ 1283 CAN_TX_TRACK_STATUS 7 "New Coasting Target" 6 "Invalid Coasting Target" 5 "Merged Target" 4 "Coasting Target" 3 "Updated Target" 2 "New Updated Target" 1 "New Target" 0 "No Target" ;
VAL_ 1282 CAN_TX_TRACK_STATUS 7 "New Coasting Target" 6 "Invalid Coasting Target" 5 "Merged Target" 4 "Coasting Target" 3 "Updated Target" 2 "New Updated Target" 1 "New Target" 0 "No Target" ;
VAL_ 1304 CAN_TX_TRACK_STATUS 7 "New Coasting Target" 6 "Invalid Coasting Target" 5 "Merged Target" 4 "Coasting Target" 3 "Updated Target" 2 "New Updated Target" 1 "New Target" 0 "No Target" ;
VAL_ 1287 CAN_TX_TRACK_STATUS 7 "New Coasting Target" 6 "Invalid Coasting Target" 5 "Merged Target" 4 "Coasting Target" 3 "Updated Target" 2 "New Updated Target" 1 "New Target" 0 "No Target" ;
VAL_ 1302 CAN_TX_TRACK_STATUS 7 "New Coasting Target" 6 "Invalid Coasting Target" 5 "Merged Target" 4 "Coasting Target" 3 "Updated Target" 2 "New Updated Target" 1 "New Target" 0 "No Target" ;
VAL_ 1294 CAN_TX_TRACK_STATUS 7 "New Coasting Target" 6 "Invalid Coasting Target" 5 "Merged Target" 4 "Coasting Target" 3 "Updated Target" 2 "New Updated Target" 1 "New Target" 0 "No Target" ;
VAL_ 1300 CAN_TX_TRACK_STATUS 7 "New Coasting Target" 6 "Invalid Coasting Target" 5 "Merged Target" 4 "Coasting Target" 3 "Updated Target" 2 "New Updated Target" 1 "New Target" 0 "No Target" ;
VAL_ 1295 CAN_TX_TRACK_STATUS 7 "New Coasting Target" 6 "Invalid Coasting Target" 5 "Merged Target" 4 "Coasting Target" 3 "Updated Target" 2 "New Updated Target" 1 "New Target" 0 "No Target" ;
VAL_ 1301 CAN_TX_TRACK_STATUS 7 "New Coasting Target" 6 "Invalid Coasting Target" 5 "Merged Target" 4 "Coasting Target" 3 "Updated Target" 2 "New Updated Target" 1 "New Target" 0 "No Target" ;
VAL_ 1289 CAN_TX_TRACK_STATUS 7 "New Coasting Target" 6 "Invalid Coasting Target" 5 "Merged Target" 4 "Coasting Target" 3 "Updated Target" 2 "New Updated Target" 1 "New Target" 0 "No Target" ;
VAL_ 1288 CAN_TX_TRACK_STATUS 7 "New Coasting Target" 6 "Invalid Coasting Target" 5 "Merged Target" 4 "Coasting Target" 3 "Updated Target" 2 "New Updated Target" 1 "New Target" 0 "No Target" ;
VAL_ 1291 CAN_TX_TRACK_STATUS 7 "New Coasting Target" 6 "Invalid Coasting Target" 5 "Merged Target" 4 "Coasting Target" 3 "Updated Target" 2 "New Updated Target" 1 "New Target" 0 "No Target" ;
VAL_ 1299 CAN_TX_TRACK_STATUS 7 "New Coasting Target" 6 "Invalid Coasting Target" 5 "Merged Target" 4 "Coasting Target" 3 "Updated Target" 2 "New Updated Target" 1 "New Target" 0 "No Target" ;
VAL_ 1296 CAN_TX_TRACK_STATUS 7 "New Coasting Target" 6 "Invalid Coasting Target" 5 "Merged Target" 4 "Coasting Target" 3 "Updated Target" 2 "New Updated Target" 1 "New Target" 0 "No Target" ;
VAL_ 1305 CAN_TX_TRACK_STATUS 7 "New Coasting Target" 6 "Invalid Coasting Target" 5 "Merged Target" 4 "Coasting Target" 3 "Updated Target" 2 "New Updated Target" 1 "New Target" 0 "No Target" ;
VAL_ 1297 CAN_TX_TRACK_STATUS 7 "New Coasting Target" 6 "Invalid Coasting Target" 5 "Merged Target" 4 "Coasting Target" 3 "Updated Target" 2 "New Updated Target" 1 "New Target" 0 "No Target" ;
VAL_ 1292 CAN_TX_TRACK_STATUS 7 "New Coasting Target" 6 "Invalid Coasting Target" 5 "Merged Target" 4 "Coasting Target" 3 "Updated Target" 2 "New Updated Target" 1 "New Target" 0 "No Target" ;
VAL_ 1309 CAN_TX_TRACK_STATUS 7 "New Coasting Target" 6 "Invalid Coasting Target" 5 "Merged Target" 4 "Coasting Target" 3 "Updated Target" 2 "New Updated Target" 1 "New Target" 0 "No Target" ;
VAL_ 1306 CAN_TX_TRACK_STATUS 7 "New Coasting Target" 6 "Invalid Coasting Target" 5 "Merged Target" 4 "Coasting Target" 3 "Updated Target" 2 "New Updated Target" 1 "New Target" 0 "No Target" ;
VAL_ 1298 CAN_TX_TRACK_STATUS 7 "New Coasting Target" 6 "Invalid Coasting Target" 5 "Merged Target" 4 "Coasting Target" 3 "Updated Target" 2 "New Updated Target" 1 "New Target" 0 "No Target" ;
VAL_ 1303 CAN_TX_TRACK_STATUS 7 "New Coasting Target" 6 "Invalid Coasting Target" 5 "Merged Target" 4 "Coasting Target" 3 "Updated Target" 2 "New Updated Target" 1 "New Target" 0 "No Target" ;
VAL_ 1308 CAN_TX_TRACK_STATUS 7 "New Coasting Target" 6 "Invalid Coasting Target" 5 "Merged Target" 4 "Coasting Target" 3 "Updated Target" 2 "New Updated Target" 1 "New Target" 0 "No Target" ;
VAL_ 1307 CAN_TX_TRACK_STATUS 7 "New Coasting Target" 6 "Invalid Coasting Target" 5 "Merged Target" 4 "Coasting Target" 3 "Updated Target" 2 "New Updated Target" 1 "New Target" 0 "No Target" ;
VAL_ 1286 CAN_TX_TRACK_STATUS 7 "New Coasting Target" 6 "Invalid Coasting Target" 5 "Merged Target" 4 "Coasting Target" 3 "Updated Target" 2 "New Updated Target" 1 "New Target" 0 "No Target" ;
VAL_ 1285 CAN_TX_TRACK_STATUS 7 "New Coasting Target" 6 "Invalid Coasting Target" 5 "Merged Target" 4 "Coasting Target" 3 "Updated Target" 2 "New Updated Target" 1 "New Target" 0 "No Target" ;
